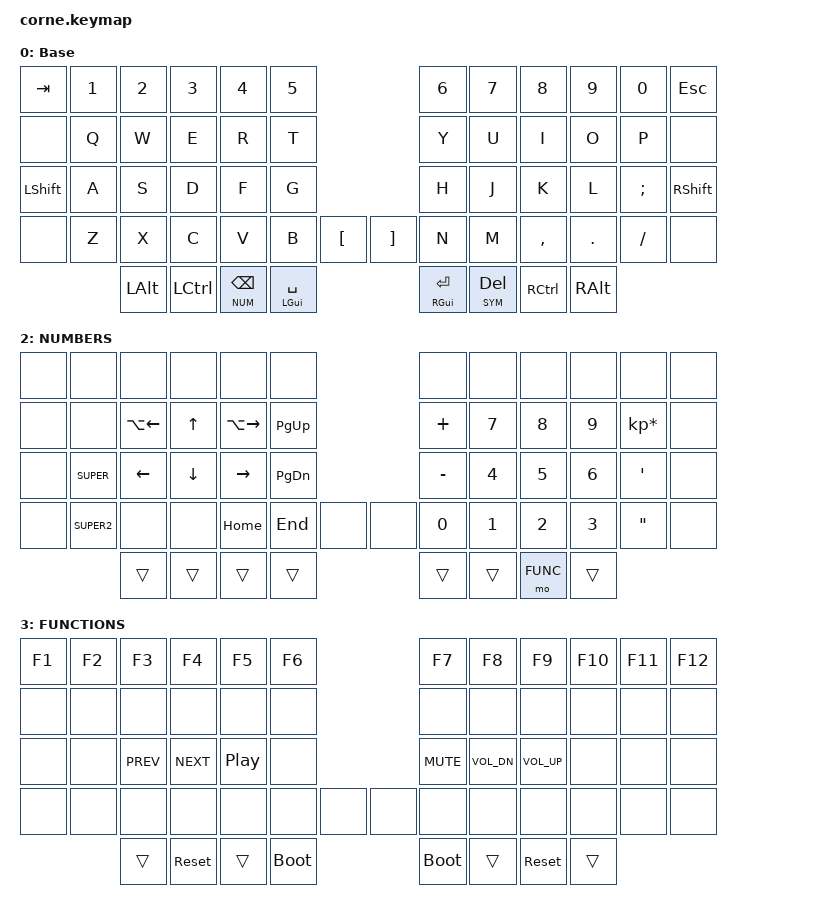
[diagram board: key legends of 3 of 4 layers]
/*
 * Copyright (c) 2020 The ZMK Contributors
 *
 * SPDX-License-Identifier: MIT
 *
 * Base Layout from: https://github.com/jporter-dev/zmk-config
 */

#include <dt-bindings/zmk/keys.h>
#include <dt-bindings/zmk/bt.h>
#include <dt-bindings/zmk/ext_power.h>
#include <behaviors.dtsi>

#define HOST_OS 2
#include "zmk-helpers/helper.h"
#include "zmk-helpers/key-labels/34.h"
#include "zmk-helpers/unicode-chars/german.dtsi"

// LAYERS
#define DEFAULT 0
#define SYM     1
#define NUM     2
#define FUNC    3

// MACROS
#define SUPER LC(LSHIFT)
#define SUPER2 LA(LC(LSHIFT))

&mt {
  tapping-term-ms = <200>;
  flavor = "tap-preferred";
};

/ {
    chosen {
        zmk;
    };

    behaviors {
        td_uml_a: td_umlaut_a {
                    compatible = "zmk,behavior-tap-dance";
                    label = "TAP_DANCE_UMLAUT_A";
                    #binding-cells = <0>;
                    tapping-term-ms = <200>;
                    bindings = <&kp A>, <&de_ae>;
                };

                td_uml_o: td_umlaut_o {
                    compatible = "zmk,behavior-tap-dance";
                    label = "TAP_DANCE_UMLAUT_O";
                    #binding-cells = <0>;
                    tapping-term-ms = <200>;
                    bindings = <&kp O>, <&de_oe>;
                };

                td_uml_u: td_umlaut_u {
                    compatible = "zmk,behavior-tap-dance";
                    label = "TAP_DANCE_UMLAUT_U";
                    #binding-cells = <0>;
                    tapping-term-ms = <200>;
                    bindings = <&kp U>, <&de_ue>;
                };

                td_uml_sz: td_umlaut_sz {
                    compatible = "zmk,behavior-tap-dance";
                    label = "TAP_DANCE_UMLAUT_SZ";
                    #binding-cells = <0>;
                    tapping-term-ms = <200>;
                    bindings = <&kp S>, <&de_eszett>;
                };
    };

    macros {
        shift_shift: shift_shift {
            label = "Shift Shift for IntelliJ";
            compatible = "zmk,behavior-macro";
            #binding-cells = <0>;
            bindings = <&macro_tap &kp LSHFT &macro_tap &kp LSHFT>;
        };
    };

    keymap {
        compatible = "zmk,keymap";

        // ---Base--------------------------------------------------------------------------------------
        default_layer {
            display-name = "Base";
            bindings = <
                // ╭───────────────┬───────────────┬───────────────┬───────────────┬───────────────┬───────────────╮                                   ╭───────────────┬───────────────┬───────────────┬───────────────┬───────────────┬───────────────╮
                //  TAB             1               2               3               4               5                                                   6               7               8               9               0               ESC
                // ├---------------┼---------------┼---------------┼---------------┼---------------┼---------------┤                                   ├---------------┼---------------┼---------------┼---------------┼---------------┼---------------┤
                    &kp TAB         &kp N1          &kp N2          &kp N3          &kp N4          &kp N5                                              &kp N6          &kp N7          &kp N8          &kp N9          &kp N0          &kp ESC
                // ├───────────────┼───────────────┼───────────────┼───────────────┼───────────────┼───────────────┤                                   ├───────────────┼───────────────┼───────────────┼───────────────┼───────────────┼───────────────┤
                //                  Q               W               E               R               T                                                   Y               U               I               O               P
                // ├---------------┼---------------┼---------------┼---------------┼---------------┼---------------┤                                   ├---------------┼---------------┼---------------┼---------------┼---------------┼---------------┤
                    &none           &kp Q           &kp W           &kp E           &kp R           &kp T                                               &kp Y           &kp U           &kp I           &kp O           &kp P           &none
                // ├───────────────┼───────────────┼───────────────┼───────────────┼───────────────┼───────────────┤                                   ├───────────────┼───────────────┼───────────────┼───────────────┼───────────────┼───────────────┤
                //  LSHIFT          A               S               D               F               G                                                   H               J               K               L               ;               RSHIFT
                // ├---------------┼---------------┼---------------┼---------------┼---------------┼---------------┤                                   ├---------------┼---------------┼---------------┼---------------┼---------------┼---------------┤
                    &kp LSHIFT      &kp A           &kp S           &kp D           &kp F           &kp G                                               &kp H           &kp J           &kp K           &kp L           &kp SEMI        &kp RSHIFT
                // ├───────────────┼───────────────┼───────────────┼───────────────┼───────────────┼───────────────┤───────────────╮   ╭───────────────├───────────────┼───────────────┼───────────────┼───────────────┼───────────────┼───────────────┤
                //                  Z               X               C               V               B               [                   ]               N               M               ,               .               /
                // ├---------------┼---------------┼---------------┼---------------┼---------------┼---------------┼---------------┤   ├---------------┼---------------┼---------------┼---------------┼---------------┼---------------┼---------------┤
                    &none           &kp Z           &kp X           &kp C           &kp V           &kp B           &kp LBKT            &kp RBKT        &kp N           &kp M           &kp COMMA       &kp DOT         &kp FSLH        &none
                // ╰───────────────┼───────────────┼───────────────┼───────────────┼───────────────┼───────────────┤───────────────╯   ╰───────────────├───────────────┼───────────────┼───────────────┼───────────────┼───────────────────────────────╯
                //                                  LALT            LCTRL           BACK SPACE      SPACE                                               ENTER           DELETE          RCTRL           RALT
                //                                 ├---------------┼---------------┼---------------┼---------------┤                                   ├---------------┼---------------┼---------------┼---------------┤
                                                    &kp LALT        &kp LCTRL       &lt NUM  BSPC   &mt LGUI SPACE                                      &mt RGUI RET    &lt SYM DEL     &kp RCTRL       &kp RALT
                //                                 ╰───────────────┴───────────────┴───────────────┴───────────────╯                                   ╰───────────────┴───────────────┴───────────────┴───────────────╯
            >;
        };


        // ---Symbols--------------------------------------------------------------------------------------
        sym_layer {
            display-name = "Symbols";
            bindings = <
                // ╭───────────────┬───────────────┬───────────────┬───────────────┬───────────────┬───────────────╮                                   ╭───────────────┬───────────────┬───────────────┬───────────────┬───────────────┬───────────────╮
                //
                // ├---------------┼---------------┼---------------┼---------------┼---------------┼---------------┤                                   ├---------------┼---------------┼---------------┼---------------┼---------------┼---------------┤
                    &none           &none           &none           &none           &none           &none                                               &none           &none           &none           &none           &none           &none
                // ├───────────────┼───────────────┼───────────────┼───────────────┼───────────────┼───────────────┤                                   ├───────────────┼───────────────┼───────────────┼───────────────┼───────────────┼───────────────┤
                //                  !               @               #               $               %                                                   ^               &               (               )               `
                // ├---------------┼---------------┼---------------┼---------------┼---------------┼---------------┤                                   ├---------------┼---------------┼---------------┼---------------┼---------------┼---------------┤
                                    &kp EXCL        &kp AT          &kp HASH        &kp DLLR        &kp PRCNT                                           &kp CARET       &kp AMPS        &kp LPAR        &kp RPAR        &mt RALT GRAVE
                // ├───────────────┼───────────────┼───────────────┼───────────────┼───────────────┼───────────────┤                                   ├───────────────┼───────────────┼───────────────┼───────────────┼───────────────┼───────────────┤
                //                  ä               ß                                                                                                   -               =               [               ]               \
                // ├---------------┼---------------┼---------------┼---------------┼---------------┼---------------┤                                   ├---------------┼---------------┼---------------┼---------------┼---------------┼---------------┤
                    &none           &de_ae          &de_eszett      &none           &none           &none                                               &kp MINUS       &kp EQUAL       &kp LBKT        &kp RBKT        &kp BSLH        &none
                // ├───────────────┼───────────────┼───────────────┼───────────────┼───────────────┼───────────────┤───────────────╮   ╭───────────────├───────────────┼───────────────┼───────────────┼───────────────┼───────────────┼───────────────┤
                //                  ü               ö                                                                                                   _               +               {               }               |               &none
                // ├---------------┼---------------┼---------------┼---------------┼---------------┼---------------┼---------------┤   ├---------------┼---------------┼---------------┼---------------┼---------------┼---------------┼---------------┤
                    &none           &de_ue          &de_oe          &none           &none           &none           &none               &none           &kp UNDER       &kp PLUS        &kp LBRC        &kp RBRC        &kp PIPE        &none
                // ╰───────────────┼───────────────┼───────────────┼───────────────┼───────────────┼───────────────┤───────────────╯   ╰───────────────├───────────────┼───────────────┼───────────────┼───────────────┼───────────────────────────────╯
                //                                                                  FUNC LAYER
                //                                 ├---------------┼---------------┼---------------┼---------------┤                                   ├---------------┼---------------┼---------------┼---------------┤
                                                    &trans          &trans          &mo FUNC        &trans                                              &trans          &trans          &trans          &trans
                //                                 ╰───────────────┴───────────────┴───────────────┴───────────────╯                                   ╰───────────────┴───────────────┴───────────────┴───────────────╯
            >;


            //bindings = <
                // ╭───────────────┬───────────────┬───────────────┬───────────────┬───────────────╮   ╭───────────────┬───────────────┬───────────────┬───────────────┬───────────────╮
                //  !               @               #               $               %                   ^               &               (               )               `
                // ├---------------┼---------------┼---------------┼---------------┼---------------┤   ├---------------┼---------------┼---------------┼---------------┼---------------┤
                 //   &kp EXCL        &kp AT          &kp HASH        &kp DLLR        &kp PRCNT           &kp CARET       &kp AMPS        &kp LPAR        &kp RPAR        &mt RALT GRAVE
                // ├───────────────┼───────────────┼───────────────┼───────────────┼───────────────┤   ├───────────────┼───────────────┼───────────────┼───────────────┼───────────────┤
                //  ä               ß                                                                   -               =               [               ]               \
                // ├---------------┼---------------┼---------------┼---------------┼---------------┤   ├---------------┼---------------┼---------------┼---------------┼---------------┤
                 //   &de_ae          &de_eszett      &none           &none           &none               &kp MINUS       &kp EQUAL       &kp LBKT        &kp RBKT        &kp BSLH
                // ├───────────────┼───────────────┼───────────────┼───────────────┼───────────────┤   ├───────────────┼───────────────┼───────────────┼───────────────┼───────────────┤
                //  ü               ö                                                                   _               +               {               }               |
                // ├---------------┼---------------┼---------------┼---------------┼---------------┤   ├---------------┼---------------┼---------------┼---------------┼---------------┤
                //    &de_ue          &de_oe          &none           &none           &none               &kp UNDER       &kp PLUS        &kp LBRC        &kp RBRC        &kp PIPE
                // ╰───────────────────────────────┼───────────────┼───────────────┼───────────────┤   ├───────────────┼───────────────┼───────────────────────────────────────────────╯
                //                                                                                                      FUNC LAYER
                //                                 ├---------------┼---------------┼---------------┤   ├---------------┼---------------┼---------------┤
                 //                                   &trans          &mo FUNC          &trans              &trans          &trans          &trans
                //                                 ╰───────────────┴───────────────┴───────────────╯   ╰───────────────┴───────────────┴───────────────╯
            //>;
        };


        // ---NUMBERS--------------------------------------------------------------------------------------
        num_layer {
            display-name = "NUMBERS";
            bindings = <
                // ╭───────────────┬───────────────┬───────────────┬───────────────┬───────────────┬───────────────╮                                   ╭───────────────┬───────────────┬───────────────┬───────────────┬───────────────┬───────────────╮
                //
                // ├---------------┼---------------┼---------------┼---------------┼---------------┼---------------┤                                   ├---------------┼---------------┼---------------┼---------------┼---------------┼---------------┤
                    &none           &none           &none           &none           &none           &none                                               &none           &none           &none           &none           &none           &none
                // ├───────────────┼───────────────┼───────────────┼───────────────┼───────────────┼───────────────┤                                   ├───────────────┼───────────────┼───────────────┼───────────────┼───────────────┼───────────────┤
                //                  JUMP WORD L     UP              JUMP WORD R     PG_UP                                                               +               7               8               9               *
                // ├---------------┼---------------┼---------------┼---------------┼---------------┼---------------┤                                   ├---------------┼---------------┼---------------┼---------------┼---------------┼---------------┤
                    &none           &none           &kp LA(LEFT)    &kp UP          &kp LA(RIGHT)   &kp PG_UP                                           &kp PLUS        &kp N7          &kp N8          &kp N9          &kp KP_MULTIPLY &none
                // ├───────────────┼───────────────┼───────────────┼───────────────┼───────────────┼───────────────┤                                   ├───────────────┼───────────────┼───────────────┼───────────────┼───────────────┼───────────────┤
                //                  SUPER           LEFT            DOWN            RIGHT           PG_DOWN                                             -               4               5               6               '
                // ├---------------┼---------------┼---------------┼---------------┼---------------┼---------------┤                                   ├---------------┼---------------┼---------------┼---------------┼---------------┼---------------┤
                    &none           &kp SUPER       &kp LEFT        &kp DOWN        &kp RIGHT       &kp PG_DN                                           &kp MINUS       &kp N4          &kp N5          &kp N6          &kp SQT         &none
                // ├───────────────┼───────────────┼───────────────┼───────────────┼───────────────┼───────────────┤───────────────╮   ╭───────────────├───────────────┼───────────────┼───────────────┼───────────────┼───────────────┼───────────────┤
                //                  SUPER2                                          HOME            END             &none               &none           0               1               2               3               "
                // ├---------------┼---------------┼---------------┼---------------┼---------------┼---------------┼---------------┤   ├---------------┼---------------┼---------------┼---------------┼---------------┼---------------┼---------------┤
                    &none           &kp SUPER2      &none           &none           &kp HOME        &kp END         &none               &none           &kp N0          &kp N1          &kp N2          &kp N3          &kp DQT         &none
                // ╰───────────────┼───────────────┼───────────────┼───────────────┼───────────────┼───────────────┤───────────────╯   ╰───────────────├───────────────┼───────────────┼───────────────┼───────────────┼───────────────────────────────╯
                //                                                                                                                                                                      FUNC LAYER
                //                                 ├---------------┼---------------┼---------------┼---------------┤                                   ├---------------┼---------------┼---------------┼---------------┤
                                                    &trans          &trans          &trans          &trans                                              &trans          &trans          &mo FUNC        &trans
                //                                 ╰───────────────┴───────────────┴───────────────┴───────────────╯                                   ╰───────────────┴───────────────┴───────────────┴───────────────╯
            >;
           //bindings = <
                // ╭───────────────┬───────────────┬───────────────┬───────────────┬───────────────╮   ╭───────────────┬───────────────┬───────────────┬───────────────┬───────────────╮
                //                  JUMP WORD L     UP              JUMP WORD R     PG_UP               +               7               8               9               *
                // ├---------------┼---------------┼---------------┼---------------┼---------------┤   ├---------------┼---------------┼---------------┼---------------┼---------------┤
                //    &none           &kp LA(LEFT)    &kp UP          &kp LA(RIGHT)   &kp PG_UP           &kp PLUS        &kp N7          &kp N8          &kp N9          &kp KP_MULTIPLY
                // ├───────────────┼───────────────┼───────────────┼───────────────┼───────────────┤   ├───────────────┼───────────────┼───────────────┼───────────────┼───────────────┤
                //  SUPER           LEFT            DOWN            RIGHT           PG_DOWN             -               4               5               6               '
                // ├---------------┼---------------┼---------------┼---------------┼---------------┤   ├---------------┼---------------┼---------------┼---------------┼---------------┤
                 //   &kp SUPER       &kp LEFT        &kp DOWN        &kp RIGHT       &kp PG_DN           &kp MINUS       &kp N4          &kp N5          &kp N6          &kp SQT
                // ├───────────────┼───────────────┼───────────────┼───────────────┼───────────────┤   ├───────────────┼───────────────┼───────────────┼───────────────┼───────────────┤
                //  SUPER2                                          HOME            END                 0               1               2               3               "
                // ├---------------┼---------------┼---------------┼---------------┼---------------┤   ├---------------┼---------------┼---------------┼---------------┼---------------┤
                //    &kp SUPER2      &none           &none           &kp HOME        &kp END             &kp N0          &kp N1          &kp N2          &kp N3          &kp DQT
                // ╰───────────────────────────────┼───────────────┼───────────────┼───────────────┤   ├───────────────┼───────────────┼───────────────────────────────────────────────╯
                //                                                  FUNC LAYER
                //                                 ├---------------┼---------------┼---------------┤   ├---------------┼---------------┼---------------┤
                //                                    &trans          &trans          &trans              &trans          &mo FUNC       &trans
                //                                 ╰───────────────┴───────────────┴───────────────╯   ╰───────────────┴───────────────┴───────────────╯
            //>;
        };


        // ---FUNCTIONS--------------------------------------------------------------------------------------
        func_layer {
            display-name = "FUNCTIONS";
            bindings = <
                // ╭───────────────┬───────────────┬───────────────┬───────────────┬───────────────┬───────────────╮                                   ╭───────────────┬───────────────┬───────────────┬───────────────┬───────────────┬───────────────╮
                //  F1              F2              F3              F4              F5              F6                                                  F7              F8              F9              F10             F11             F12
                // ├---------------┼---------------┼---------------┼---------------┼---------------┼---------------┤                                   ├---------------┼---------------┼---------------┼---------------┼---------------┼---------------┤
                    &kp F1          &kp F2          &kp F3          &kp F4          &kp F5          &kp F6                                              &kp F7          &kp F8          &kp F9          &kp F10         &kp F11         &kp F12
                // ├───────────────┼───────────────┼───────────────┼───────────────┼───────────────┼───────────────┤                                   ├───────────────┼───────────────┼───────────────┼───────────────┼───────────────┼───────────────┤
                //
                // ├---------------┼---------------┼---------------┼---------------┼---------------┼---------------┤                                   ├---------------┼---------------┼---------------┼---------------┼---------------┼---------------┤
                    &none           &none           &none           &none           &none           &none                                               &none           &none           &none           &none           &none           &none
                // ├───────────────┼───────────────┼───────────────┼───────────────┼───────────────┼───────────────┤                                   ├───────────────┼───────────────┼───────────────┼───────────────┼───────────────┼───────────────┤
                //                                  PREV            NEXT            PLAY_PAUSE                                                          MUTE            VOL_DOWN        VOL_UP
                // ├---------------┼---------------┼---------------┼---------------┼---------------┼---------------┤                                   ├---------------┼---------------┼---------------┼---------------┼---------------┼---------------┤
                    &none           &none           &kp C_PREV      &kp C_NEXT      &kp C_PLAY_PAUSE &none                                              &kp C_MUTE      &kp C_VOL_DN    &kp C_VOL_UP    &none           &none           &none
                // ├───────────────┼───────────────┼───────────────┼───────────────┼───────────────┼───────────────┤───────────────╮   ╭───────────────├───────────────┼───────────────┼───────────────┼───────────────┼───────────────┼───────────────┤
                //
                // ├---------------┼---------------┼---------------┼---------------┼---------------┼---------------┼---------------┤   ├---------------┼---------------┼---------------┼---------------┼---------------┼---------------┼---------------┤
                    &none           &none           &none           &none           &none           &none           &none               &none           &none           &none           &none           &none           &none           &none
                // ╰───────────────┼───────────────┼───────────────┼───────────────┼───────────────┼───────────────┤───────────────╯   ╰───────────────├───────────────┼───────────────┼───────────────┼───────────────┼───────────────────────────────╯
                //
                //                                 ├---------------┼---------------┼---------------┼---------------┤                                   ├---------------┼---------------┼---------------┼---------------┤
                                                    &trans          &sys_reset      &trans          &bootloader                                         &bootloader     &trans          &sys_reset      &trans
                //                                 ╰───────────────┴───────────────┴───────────────┴───────────────╯                                   ╰───────────────┴───────────────┴───────────────┴───────────────╯
            >;
           // bindings = <
                // ╭───────────────┬───────────────┬───────────────┬───────────────┬───────────────╮   ╭───────────────┬───────────────┬───────────────┬───────────────┬───────────────╮
                //  F1              F2              F3              F4              F5                  F6              F7              F8              F9              F10
                // ├---------------┼---------------┼---------------┼---------------┼---------------┤   ├---------------┼---------------┼---------------┼---------------┼---------------┤
                 //   &kp F1          &kp F2          &kp F3          &kp F4          &kp F5              &kp F6          &kp F7          &kp F8          &kp F9          &kp F10
                // ├───────────────┼───────────────┼───────────────┼───────────────┼───────────────┤   ├───────────────┼───────────────┼───────────────┼───────────────┼───────────────┤
                //                                  PREV            NEXT            PLAY_PAUSE          MUTE            VOL_DOWN        VOL_UP                          F11
                // ├---------------┼---------------┼---------------┼---------------┼---------------┤   ├---------------┼---------------┼---------------┼---------------┼---------------┤
                //    &none           &none           &kp C_PREV      &kp C_NEXT      &kp C_PLAY_PAUSE    &kp C_MUTE      &kp C_VOL_DN    &kp C_VOL_UP    &none           &kp F11
                // ├───────────────┼───────────────┼───────────────┼───────────────┼───────────────┤   ├───────────────┼───────────────┼───────────────┼───────────────┼───────────────┤
                //                                                                                                                                                      F12
                // ├---------------┼---------------┼---------------┼---------------┼---------------┤   ├---------------┼---------------┼---------------┼---------------┼---------------┤
                //    &none           &none           &none           &none           &none               &none           &none           &none           &none           &kp F12
                // ╰───────────────────────────────┼───────────────┼───────────────┼───────────────┤   ├───────────────┼───────────────┼───────────────────────────────────────────────╯
                //
                //                                 ├---------------┼---------------┼---------------┤   ├---------------┼---------------┼---------------┤
                //                                    &sys_reset      &trans          &bootloader         &bootloader     &trans          &sys_reset
                //                                 ╰───────────────┴───────────────┴───────────────╯   ╰───────────────┴───────────────┴───────────────╯
            //>;
        };
    };
};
